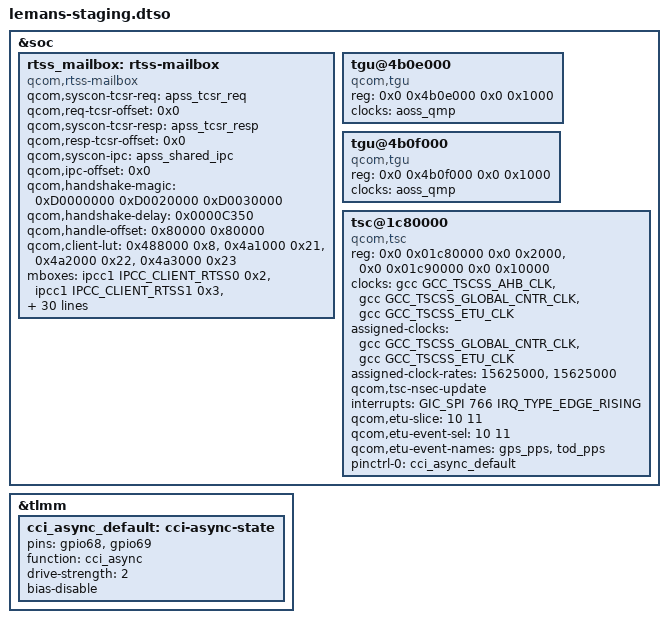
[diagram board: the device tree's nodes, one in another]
// SPDX-License-Identifier: BSD-3-Clause
/*
 * Copyright (c) Qualcomm Technologies, Inc. and/or its subsidiaries.
 *
 * Lemans staging overlay - add staging-specific device tree modifications here.
 */

/dts-v1/;
/plugin/;
#include <dt-bindings/interrupt-controller/arm-gic.h>
#include <dt-bindings/interrupt-controller/irq.h>
#include <dt-bindings/clock/qcom,sa8775p-gcc.h>
#include <dt-bindings/mailbox/qcom-ipcc.h>

&soc {
	rtss_mailbox: rtss-mailbox {
		compatible = "qcom,rtss-mailbox";
		qcom,syscon-tcsr-req  = <&apss_tcsr_req>;
		qcom,req-tcsr-offset  = <0x0>;
		qcom,syscon-tcsr-resp = <&apss_tcsr_resp>;
		qcom,resp-tcsr-offset = <0x0>;
		qcom,syscon-ipc = <&apss_shared_ipc>;
		qcom,ipc-offset = <0x0>;
		qcom,handshake-magic = <0xD0000000 0xD0020000 0xD0030000>;
		qcom,handshake-delay = <0x0000C350>;
		qcom,handle-offset   = <0x80000 0x80000>;
		qcom,client-lut = <0x488000 0x8>, <0x4a1000 0x21>, <0x4a2000 0x22>, <0x4a3000 0x23>;
		mboxes = <&ipcc1 IPCC_CLIENT_RTSS0 0x2>,
			<&ipcc1 IPCC_CLIENT_RTSS1 0x3>,
			<&ipcc1 IPCC_CLIENT_RTSS0 0x4>,
			<&ipcc1 IPCC_CLIENT_RTSS0 0x5>,
			<&ipcc1 IPCC_CLIENT_RTSS0 0x6>,
			<&ipcc1 IPCC_CLIENT_RTSS0 0x7>,
			<&ipcc1 IPCC_CLIENT_RTSS2 0x8>,
			<&ipcc1 IPCC_CLIENT_RTSS1 0x9>,
			<&ipcc1 IPCC_CLIENT_RTSS2 0xa>,
			<&ipcc1 IPCC_CLIENT_RTSS1 0xb>,
			<&ipcc1 IPCC_CLIENT_RTSS0 0xc>,
			<&ipcc1 IPCC_CLIENT_RTSS0 0xd>,
			<&ipcc1 IPCC_CLIENT_RTSS1 0xe>,
			<&ipcc1 IPCC_CLIENT_RTSS2 0xf>,
			<&ipcc1 IPCC_CLIENT_RTSS3 0x10>;
		interrupts-extended = <&ipcc1 IPCC_CLIENT_RTSS0 0x2 IRQ_TYPE_EDGE_RISING>,
			<&ipcc1 IPCC_CLIENT_RTSS1 0x3 IRQ_TYPE_EDGE_RISING>,
			<&ipcc1 IPCC_CLIENT_RTSS0 0x4 IRQ_TYPE_EDGE_RISING>,
			<&ipcc1 IPCC_CLIENT_RTSS0 0x5 IRQ_TYPE_EDGE_RISING>,
			<&ipcc1 IPCC_CLIENT_RTSS0 0x6 IRQ_TYPE_EDGE_RISING>,
			<&ipcc1 IPCC_CLIENT_RTSS0 0x7 IRQ_TYPE_EDGE_RISING>,
			<&ipcc1 IPCC_CLIENT_RTSS2 0x8 IRQ_TYPE_EDGE_RISING>,
			<&ipcc1 IPCC_CLIENT_RTSS1 0x9 IRQ_TYPE_EDGE_RISING>,
			<&ipcc1 IPCC_CLIENT_RTSS2 0xa IRQ_TYPE_EDGE_RISING>,
			<&ipcc1 IPCC_CLIENT_RTSS1 0xb IRQ_TYPE_EDGE_RISING>,
			<&ipcc1 IPCC_CLIENT_RTSS0 0xc IRQ_TYPE_EDGE_RISING>,
			<&ipcc1 IPCC_CLIENT_RTSS0 0xd IRQ_TYPE_EDGE_RISING>,
			<&ipcc1 IPCC_CLIENT_RTSS1 0xe IRQ_TYPE_EDGE_RISING>,
			<&ipcc1 IPCC_CLIENT_RTSS2 0xf IRQ_TYPE_EDGE_RISING>,
			<&ipcc1 IPCC_CLIENT_RTSS3 0x10 IRQ_TYPE_EDGE_RISING>;
		memory-region = <&sail_mailbox_mem>,
				        <&sail_ota_mem>;
		status = "okay";
	};

	tgu@4b0e000 {
		compatible = "qcom,tgu", "arm,primecell";
		reg = <0x0 0x4b0e000 0x0 0x1000>;

		clocks = <&aoss_qmp>;
		clock-names = "apb_pclk";
	};

	tgu@4b0f000 {
		compatible = "qcom,tgu", "arm,primecell";
		reg = <0x0 0x4b0f000 0x0 0x1000>;

		clocks = <&aoss_qmp>;
		clock-names = "apb_pclk";
	};

	tsc@1c80000 {
		compatible = "qcom,tsc";
		reg = <0x0 0x01c80000 0x0 0x2000>,
		      <0x0 0x01c90000 0x0 0x10000>;
		reg-names = "tsc", "etu";

		clocks = <&gcc GCC_TSCSS_AHB_CLK>,
			 <&gcc GCC_TSCSS_GLOBAL_CNTR_CLK>,
			 <&gcc GCC_TSCSS_ETU_CLK>;
		clock-names = "cfg_ahb", "cntr", "etu";

		assigned-clocks = <&gcc GCC_TSCSS_GLOBAL_CNTR_CLK>,
				  <&gcc GCC_TSCSS_ETU_CLK>;
		assigned-clock-rates = <15625000>, <15625000>;

		qcom,tsc-nsec-update;

		interrupts = <GIC_SPI 766 IRQ_TYPE_EDGE_RISING>;
		interrupt-names = "etu_summary_irq";

		qcom,etu-slice = <10 11>;
		qcom,etu-event-sel = <10 11>;
		qcom,etu-event-names = "gps_pps", "tod_pps";

		pinctrl-names = "default";
		pinctrl-0 = <&cci_async_default>;
	};
};

&tlmm {
	cci_async_default: cci-async-state {
		pins = "gpio68", "gpio69";
		function = "cci_async";
		drive-strength = <2>;
		bias-disable;
	};
};
